# HDSC_HC32L130F8UA register map
Vendor: HDSC Co.Ltd; Series: ARMCM0P; File version: 1.2
CPU: CM0 r0p0, little endian, no MPU, no FPU, 3 interrupt priority bits
Registers are 32-bit, read-write, reset 0x0 unless marked. A register's access mark holds for its fields unless they carry their own. Offsets are from the block's base; [hi:lo] are bit positions.

## RAM
Base 0x40020400
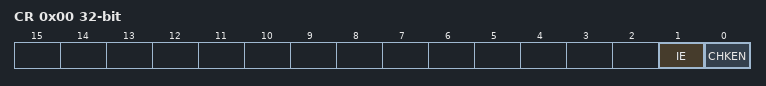
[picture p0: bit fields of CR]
0x00 CR
  [1] IE, [0] CHKEN
0x04 ERRADDR ro
  [12:0] ERRADDR
0x08 IFR ro
  [0] ERR
0x0C ICLR wo reset 0x1
  [0] ERRCLR

## RESET
Base 0x4000201C
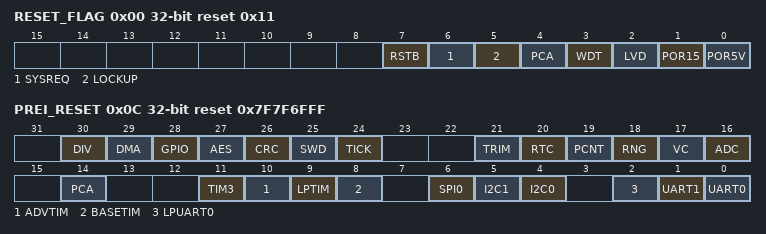
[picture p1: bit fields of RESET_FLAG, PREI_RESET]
0x00 RESET_FLAG reset 0x11
  [7] RSTB, [6] SYSREQ, [5] LOCKUP, [4] PCA, [3] WDT, [2] LVD, [1] POR15, [0] POR5V
0x0C PREI_RESET reset 0x7F7F6FFF
  [30] DIV, [29] DMA, [28] GPIO, [27] AES, [26] CRC, [25] SWD, [24] TICK, [21] TRIM, [20] RTC, [19] PCNT, [18] RNG, [17] VC, [16] ADC, [14] PCA, [11] TIM3, [10] ADVTIM, [9] LPTIM, [8] BASETIM, [6] SPI0, [5] I2C1, [4] I2C0, [2] LPUART0, [1] UART1, [0] UART0

## RNG
Base 0x40004C00
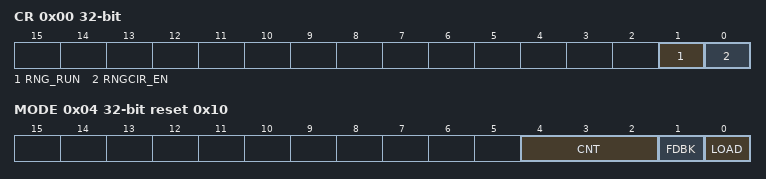
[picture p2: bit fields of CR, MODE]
0x00 CR
  [1] RNG_RUN, [0] RNGCIR_EN
0x04 MODE reset 0x10
  [4:2] CNT, [1] FDBK, [0] LOAD
0x0C DATA0 ro
0x10 DATA1 ro

## RTC
Base 0x40001400
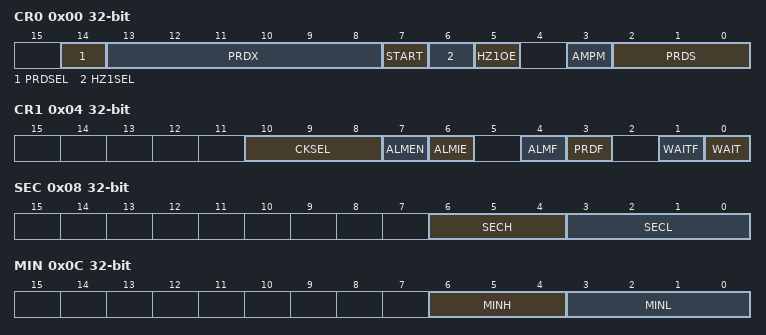
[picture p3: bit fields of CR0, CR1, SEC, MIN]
0x00 CR0
  [14] PRDSEL, [13:8] PRDX, [7] START, [6] HZ1SEL, [5] HZ1OE, [3] AMPM, [2:0] PRDS
0x04 CR1
  [10:8] CKSEL, [7] ALMEN, [6] ALMIE, [4] ALMF, [3] PRDF, [1] WAITF, [0] WAIT
0x08 SEC
  [6:4] SECH, [3:0] SECL
0x0C MIN
  [6:4] MINH, [3:0] MINL
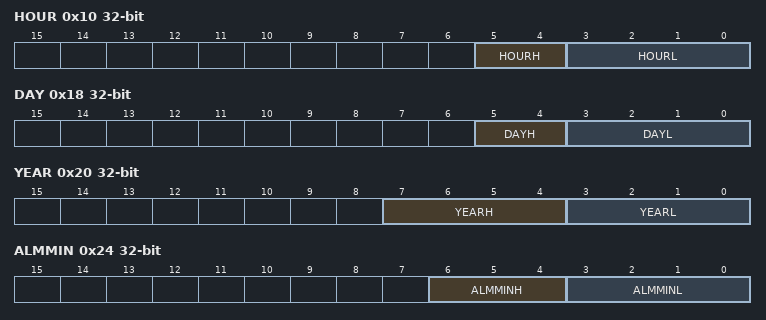
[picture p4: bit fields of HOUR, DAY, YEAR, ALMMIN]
0x10 HOUR
  [5:4] HOURH, [3:0] HOURL
0x14 WEEK
  [2:0] WEEK
0x18 DAY
  [5:4] DAYH, [3:0] DAYL
0x1C MON
  [4:0] MON
0x20 YEAR
  [7:4] YEARH, [3:0] YEARL
0x24 ALMMIN
  [6:4] ALMMINH, [3:0] ALMMINL
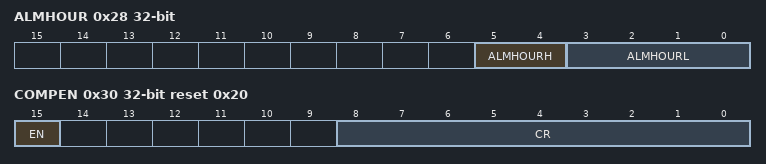
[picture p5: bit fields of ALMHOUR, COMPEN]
0x28 ALMHOUR
  [5:4] ALMHOURH, [3:0] ALMHOURL
0x2C ALMWEEK
  [6:0] ALMWEEK
0x30 COMPEN reset 0x20
  [15] EN, [8:0] CR

## SPI0 — desc SPI
Base 0x40000800
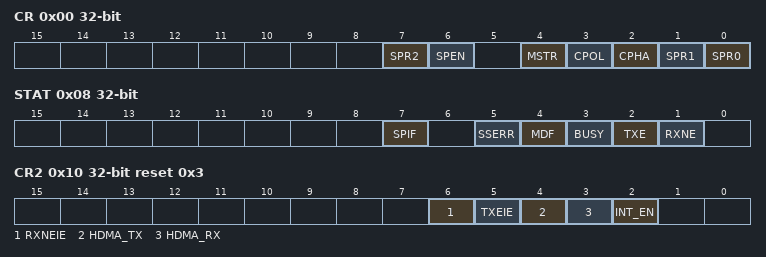
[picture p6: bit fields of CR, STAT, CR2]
0x00 CR
  [7] SPR2, [6] SPEN, [4] MSTR, [3] CPOL, [2] CPHA, [1] SPR1, [0] SPR0
0x04 SSN reset 0x1
  [0] SSN
0x08 STAT ro
  [7] SPIF, [5] SSERR, [4] MDF, [3] BUSY, [2] TXE, [1] RXNE
0x0C DATA
  [7:0] DAT
0x10 CR2 reset 0x3
  [6] RXNEIE, [5] TXEIE, [4] HDMA_TX, [3] HDMA_RX, [2] INT_EN
0x14 ICLR wo reset 0xFFFFFFFF
  [0] INT_CLR

## SYSCTRL
Base 0x40002000
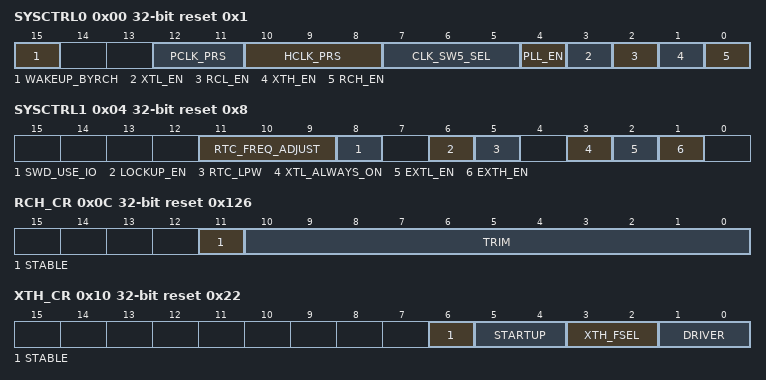
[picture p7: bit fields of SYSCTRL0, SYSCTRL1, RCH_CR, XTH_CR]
0x00 SYSCTRL0 reset 0x1
  [15] WAKEUP_BYRCH, [12:11] PCLK_PRS, [10:8] HCLK_PRS, [7:5] CLK_SW5_SEL, [4] PLL_EN, [3] XTL_EN, [2] RCL_EN, [1] XTH_EN, [0] RCH_EN
0x04 SYSCTRL1 reset 0x8
  [11:9] RTC_FREQ_ADJUST, [8] SWD_USE_IO, [6] LOCKUP_EN, [5] RTC_LPW, [3] XTL_ALWAYS_ON, [2] EXTL_EN, [1] EXTH_EN
0x08 SYSCTRL2 wo
  [15:0] SYSCTRL2
0x0C RCH_CR reset 0x126
  [11] STABLE ro, [10:0] TRIM
0x10 XTH_CR reset 0x22
  [6] STABLE ro, [5:4] STARTUP, [3:2] XTH_FSEL, [1:0] DRIVER
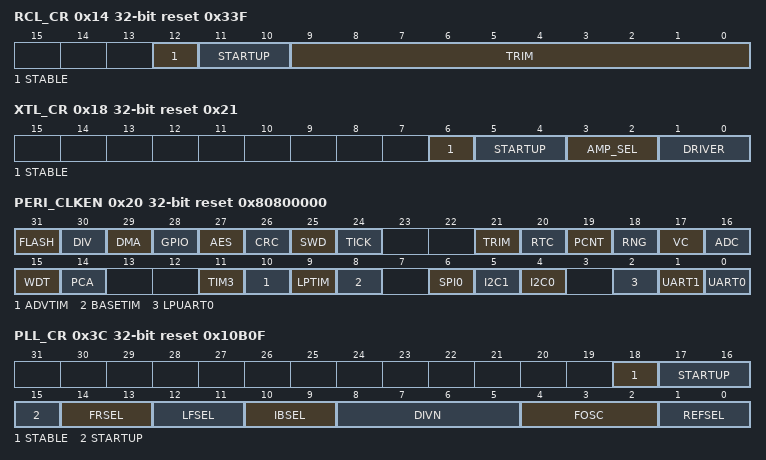
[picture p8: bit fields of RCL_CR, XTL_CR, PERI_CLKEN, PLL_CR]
0x14 RCL_CR reset 0x33F
  [12] STABLE ro, [11:10] STARTUP, [9:0] TRIM
0x18 XTL_CR reset 0x21
  [6] STABLE ro, [5:4] STARTUP, [3:2] AMP_SEL, [1:0] DRIVER
0x20 PERI_CLKEN reset 0x80800000
  [31] FLASH, [30] DIV, [29] DMA, [28] GPIO, [27] AES, [26] CRC, [25] SWD, [24] TICK, [21] TRIM, [20] RTC, [19] PCNT, [18] RNG, [17] VC, [16] ADC, [15] WDT, [14] PCA, [11] TIM3, [10] ADVTIM, [9] LPTIM, [8] BASETIM, [6] SPI0, [5] I2C1, [4] I2C0, [2] LPUART0, [1] UART1, [0] UART0
0x3C PLL_CR reset 0x10B0F (reset mask 0x3FFFF)
  [18] STABLE, [17:15] STARTUP, [14:13] FRSEL, [12:11] LFSEL, [10:9] IBSEL, [8:5] DIVN, [4:2] FOSC, [1:0] REFSEL

## TIM0_MODE0
Base 0x40000C00
Same registers: TIM1_MODE0 0x40000D00, TIM2_MODE0 0x40000E00, TIM3_MODE0 0x40005800
0x00 ARR
  [15:0] ARR
0x04 CNT
  [15:0] CNT
0x08 CNT32
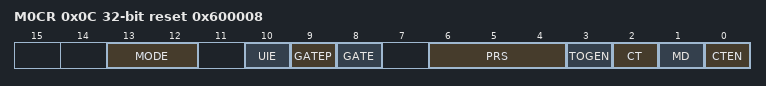
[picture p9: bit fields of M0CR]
0x0C M0CR reset 0x600008
  [13:12] MODE, [10] UIE, [9] GATEP, [8] GATE, [6:4] PRS, [3] TOGEN, [2] CT, [1] MD, [0] CTEN
0x10 IFR ro
  [0] UIF
0x14 ICLR wo reset 0xFFFF
  [0] UIF
0x30 DTR
  [12] MOE

## TIM0_MODE1
Base 0x40000C00; alternate view of TIM0_MODE0
0x04 CNT
  [15:0] CNT
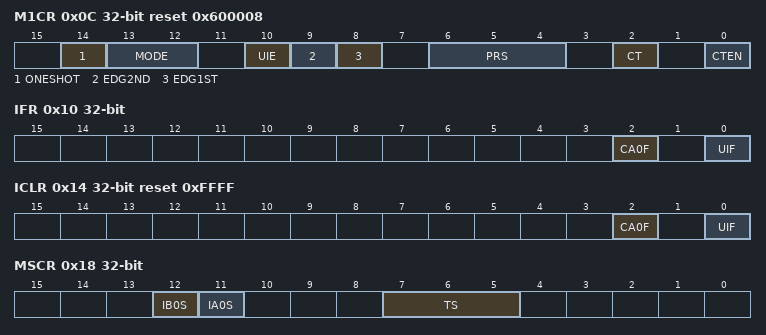
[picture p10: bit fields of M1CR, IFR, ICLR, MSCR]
0x0C M1CR reset 0x600008
  [14] ONESHOT, [13:12] MODE, [10] UIE, [9] EDG2ND, [8] EDG1ST, [6:4] PRS, [2] CT, [0] CTEN
0x10 IFR ro
  [2] CA0F, [0] UIF
0x14 ICLR wo reset 0xFFFF
  [2] CA0F, [0] UIF
0x18 MSCR
  [12] IB0S, [11] IA0S, [7:5] TS
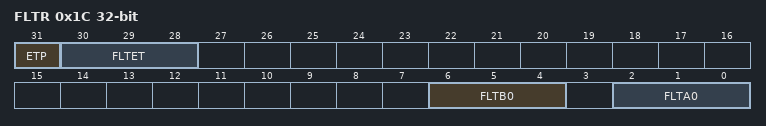
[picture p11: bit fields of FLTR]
0x1C FLTR
  [31] ETP, [30:28] FLTET, [6:4] FLTB0, [2:0] FLTA0
0x24 CR0 reset 0x3000
  [8] CIEA
0x3C CCR0A
  [15:0] CCR0A

## TIM1_MODE1
Base 0x40000D00; alternate view of TIM1_MODE0
Registers as TIM0_MODE1.

## TIM2_MODE1
Base 0x40000E00; alternate view of TIM2_MODE0
Registers as TIM0_MODE1.

## TIM3_MODE1
Base 0x40005800; alternate view of TIM3_MODE0
Registers as TIM0_MODE1.
